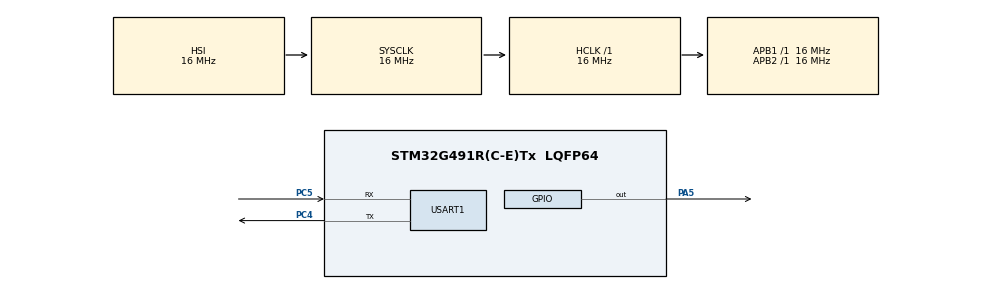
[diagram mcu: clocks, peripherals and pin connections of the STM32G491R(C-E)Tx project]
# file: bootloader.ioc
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Mcu.Family=STM32G4
Mcu.Name=STM32G491R(C-E)Tx
Mcu.Package=LQFP64
NVIC.PriorityGroup=NVIC_PRIORITYGROUP_4
NVIC.TIM6_DAC_IRQn=true\:15\:0\:false\:false\:true\:false\:true\:true
NVIC.TimeBase=TIM6_DAC_IRQn
NVIC.TimeBaseIP=TIM6
PA13.Mode=Serial_Wire
PA13.Signal=SYS_JTMS-SWDIO
PA14.Mode=Serial_Wire
PA14.Signal=SYS_JTCK-SWCLK
PA5.Signal=GPIO_Output
PC4.Mode=Asynchronous
PC4.Signal=USART1_TX
PC5.Mode=Asynchronous
PC5.Signal=USART1_RX
ProjectManager.HeapSize=0x200
ProjectManager.StackSize=0x400
ProjectManager.TargetToolchain=STM32CubeIDE
RCC.ADC12Freq_Value=16000000
RCC.ADC345Freq_Value=16000000
RCC.AHBFreq_Value=16000000
RCC.APB1Freq_Value=16000000
RCC.APB1TimFreq_Value=16000000
RCC.APB2Freq_Value=16000000
RCC.APB2TimFreq_Value=16000000
RCC.CortexFreq_Value=16000000
RCC.EXTERNAL_CLOCK_VALUE=12288000
RCC.HCLKFreq_Value=16000000
RCC.HSE_VALUE=24000000
RCC.HSI48_VALUE=48000000
RCC.HSI_VALUE=16000000
RCC.LSE_VALUE=32768
RCC.PLLM=RCC_PLLM_DIV4
RCC.PLLN=85
RCC.RTCClockSelection=RCC_RTCCLKSOURCE_LSE
RCC.SYSCLKFreq_VALUE=16000000
RCC.USBFreq_Value=48000000
RCC.VCOOutputFreq_Value=340000000
USART1.VirtualMode-Asynchronous=VM_ASYNC
VP_SYS_VS_DBSignals.Mode=DisableDeadBatterySignals
VP_SYS_VS_tim6.Mode=TIM6
VP_TIM1_VS_ClockSourceINT.Mode=Internal
board=NUCLEO-G491RE

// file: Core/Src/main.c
/* USER CODE BEGIN Header */
/**
  ******************************************************************************
  * @file           : main.c
  * @brief          : Main program body
  ******************************************************************************
  * @attention
  *
  * Copyright (c) 2026 STMicroelectronics.
  * All rights reserved.
  *
  * This software is licensed under terms that can be found in the LICENSE file
  * in the root directory of this software component.
  * If no LICENSE file comes with this software, it is provided AS-IS.
  *
  ******************************************************************************
  */
/* USER CODE END Header */
#include "main.h"
#include "tim.h"
#include "usart.h"
#include "gpio.h"

/* USER CODE BEGIN Includes */
#include <math.h>
#include <stdio.h>
#include <stdbool.h>

/* USER CODE END Includes */

/* USER CODE BEGIN PM */
#define APP_START	0x08008000
#define BOOT_FLAG (*((volatile uint32_t*)0x2001BFFC))
// RAM staging buffer size: 64 KB fits comfortably in the 112 KB of RAM.
#define FW_RAM_MAX  0x10000

/* USER CODE END PM */

/* USER CODE BEGIN PV */

uint32_t at_app_start;

/* USER CODE END PV */

void SystemClock_Config(void);

/* USER CODE BEGIN 0 */
void disable(){
				// 1. Disable SysTick
				SysTick->CTRL = 0;
				SysTick->LOAD = 0;
				SysTick->VAL  = 0;

				// 2. De-initialize peripherals used (example)
				HAL_UART_DeInit(&huart1);

				// 3. Clear NVIC registers
				for (uint8_t i = 0; i < 8; i++) {
					NVIC->ICER[i] = 0xFFFFFFFF;
					NVIC->ICPR[i] = 0xFFFFFFFF;
				}

				// 4. Global lock
				__disable_irq();
		  }

void reset_handler(){
			  //reset handler at stack_start + 4u. contains address to function
			  //which must be loaded to pc and must be called. it will later call main()
			  uint32_t reset_handler_adr = *(uint32_t*)(APP_START + 4u); //read reset handler adr

			  void (*reset_handler)(void); //decleare function pointer
			  reset_handler = (void (*)(void)) reset_handler_adr; //define function and cast as function pointer
			  reset_handler(); //call function
		  }

void set_main_nvic(){
	SCB->VTOR = APP_START; //set vector table
	}

void set_msp(){
			  uint32_t app_start =*(uint32_t*) (APP_START);
			  __set_MSP(app_start); //set main stack pointer to start of stack address for main function
			}
void enter_main(){
			  disable();
			  set_main_nvic();
			  set_msp();
			  __enable_irq();
			  reset_handler();
}
uint32_t pg_err;
void erase_flash(){
	  FLASH_EraseInitTypeDef flash_struct={
			  .TypeErase = FLASH_TYPEERASE_PAGES,
			  .Banks = FLASH_BANK_1,
			  .Page = (APP_START - FLASH_BASE) / PAGESIZE ,
			  .NbPages = (FLASH_SIZE - (APP_START - FLASH_BASE)) / PAGESIZE
	  };
	  HAL_FLASHEx_Erase(&flash_struct, &pg_err); //erase all of flash, for now
}

uint32_t size;
bool get_project_size(){
	uint8_t discard;
	// drain any stale/misaligned bytes before attempting the 4-byte receive
	while (HAL_UART_Receive(&huart1, &discard, 1, 10) == HAL_OK) {}
	__HAL_UART_CLEAR_OREFLAG(&huart1);
	while(1){
		HAL_StatusTypeDef status = HAL_UART_Receive(&huart1, (uint8_t*) &size, 4, 6000);
		if (size > 0 && size <= FW_RAM_MAX && status == HAL_OK){
			return true;
		}
		// drain and clear before retrying
		while (HAL_UART_Receive(&huart1, &discard, 1, 10) == HAL_OK) {}
		__HAL_UART_CLEAR_OREFLAG(&huart1);
	}
}

uint8_t firmware_buffer[8];
uint64_t double_word;

// RAM staging buffer: receive the whole firmware first, then flash from here.
uint8_t firmware_ram[FW_RAM_MAX];

uint64_t pack_double_word(uint8_t *buffer)
{
    uint64_t word = 0;

    word |= ((uint64_t)buffer[0] << 0);
    word |= ((uint64_t)buffer[1] << 8);
    word |= ((uint64_t)buffer[2] << 16);
    word |= ((uint64_t)buffer[3] << 24);
    word |= ((uint64_t)buffer[4] << 32);
    word |= ((uint64_t)buffer[5] << 40);
    word |= ((uint64_t)buffer[6] << 48);
    word |= ((uint64_t)buffer[7] << 56);

    return word;
}

HAL_StatusTypeDef write_to_flash(uint32_t project_size)
{
    // 1. Receive the entire firmware into RAM in one go. No flash programming
    //    happens between bytes, so the CPU keeps up with the 115200 baud stream
    //    and no bytes are lost to UART overrun.
    HAL_StatusTypeDef uart_status =
        HAL_UART_Receive(&huart1, firmware_ram, project_size, HAL_MAX_DELAY);

    if (uart_status != HAL_OK)
    {
        return uart_status;
    }

    // 2. Flash from the RAM buffer, one double-word (8 bytes) at a time.
    uint32_t start_adr = APP_START;
    uint32_t bytes_written = 0;

    while (bytes_written < project_size)
    {
        // Fill with 0xFF in case this is the last partial chunk
        for (uint8_t i = 0; i < 8; i++)
        {
            uint32_t idx = bytes_written + i;
            firmware_buffer[i] = (idx < project_size) ? firmware_ram[idx] : 0xFF;
        }

        double_word = pack_double_word(firmware_buffer);

        HAL_StatusTypeDef flash_status =
            HAL_FLASH_Program(FLASH_TYPEPROGRAM_DOUBLEWORD, start_adr, double_word);

        if (flash_status != HAL_OK)
        {
            return flash_status;
        }

        start_adr += 8;
        bytes_written += 8;
    }

    return HAL_OK;
}

/* USER CODE END 0 */

int main(void)
{

  /* MCU Configuration--------------------------------------------------------*/

  /* Reset of all peripherals, Initializes the Flash interface and the Systick. */
  HAL_Init();

  /* Configure the system clock */
  SystemClock_Config();

  /* Initialize all configured peripherals */
  MX_GPIO_Init();
  MX_USART1_UART_Init();
  MX_TIM1_Init();
  /* USER CODE BEGIN 2 */
  uint8_t rx_byte;
  if (BOOT_FLAG == 0xDEADBEEF){
    //HAL_UART_Receive(&huart1, &rx_byte, 1, 200);
    BOOT_FLAG = 0x00; //clear flag
	  //enter update mode
	  printf("U received\n");

	  HAL_FLASH_Unlock();

	  if (get_project_size()){
		  printf("size received\n");
		  printf("receiving and writing %lu bytes\n", size);
	  }

	  erase_flash();

	  printf("erased flash\n");

	  write_to_flash(size);

	  HAL_FLASH_Lock();
	  printf("written to flash, entering main\n");
	  enter_main();

  }
  HAL_StatusTypeDef status;
  status = HAL_UART_Receive(&huart1, &rx_byte, 1, 9000);

  while (1){
	  if (status == HAL_OK && rx_byte=='U'){
		  //enter update mode
		  printf("U received\n");

		  HAL_FLASH_Unlock();

		  if (get_project_size()){
			  printf("size received\n");
			  printf("receiving and writing %lu bytes\n", size);
		  }

		  erase_flash();
		  printf("erased flash\n");

		  HAL_StatusTypeDef write_status = write_to_flash(size);

		  HAL_FLASH_Lock();
		  printf("written to flash, entering main\n");
		  enter_main();

	  } else{
		  at_app_start = *(uint32_t*) APP_START; //read whats written at start of vector table
		  if (0x20000000 < at_app_start && at_app_start <= 0x2001C000){ //this range was chosen since it must be a value in the ram

			  enter_main(); //the value at app start address is valid and holds location of top of vector table
		  }

		  else{
			  //printf("waiting...\r\n");
			  status = HAL_UART_Receive(&huart1, &rx_byte, 1, HAL_MAX_DELAY); //keepwaiting in bootloader mode, if byte received return to top of while loop
		  }
	  }
  }

  /* USER CODE END 2 */

  /* Infinite loop */
  while (1)
  {

  }
}

void SystemClock_Config(void)
{
  RCC_OscInitTypeDef RCC_OscInitStruct = {0};
  RCC_ClkInitTypeDef RCC_ClkInitStruct = {0};

  /** Configure the main internal regulator output voltage
  */
  HAL_PWREx_ControlVoltageScaling(PWR_REGULATOR_VOLTAGE_SCALE1);

  /** Initializes the RCC Oscillators according to the specified parameters
  * in the RCC_OscInitTypeDef structure.
  */
  RCC_OscInitStruct.OscillatorType = RCC_OSCILLATORTYPE_HSI;
  RCC_OscInitStruct.HSIState = RCC_HSI_ON;
  RCC_OscInitStruct.HSICalibrationValue = RCC_HSICALIBRATION_DEFAULT;
  RCC_OscInitStruct.PLL.PLLState = RCC_PLL_NONE;
  if (HAL_RCC_OscConfig(&RCC_OscInitStruct) != HAL_OK)
  {
    Error_Handler();
  }

  /** Initializes the CPU, AHB and APB buses clocks
  */
  RCC_ClkInitStruct.ClockType = RCC_CLOCKTYPE_HCLK|RCC_CLOCKTYPE_SYSCLK
                              |RCC_CLOCKTYPE_PCLK1|RCC_CLOCKTYPE_PCLK2;
  RCC_ClkInitStruct.SYSCLKSource = RCC_SYSCLKSOURCE_HSI;
  RCC_ClkInitStruct.AHBCLKDivider = RCC_SYSCLK_DIV1;
  RCC_ClkInitStruct.APB1CLKDivider = RCC_HCLK_DIV1;
  RCC_ClkInitStruct.APB2CLKDivider = RCC_HCLK_DIV1;

  if (HAL_RCC_ClockConfig(&RCC_ClkInitStruct, FLASH_LATENCY_0) != HAL_OK)
  {
    Error_Handler();
  }
}

void HAL_TIM_PeriodElapsedCallback(TIM_HandleTypeDef *htim)
{
  if (htim->Instance == TIM6)
  {
    HAL_IncTick();
  }
}

void Error_Handler(void)
{
  __disable_irq();
  while (1)
  {
  }
}
